VERSION ""

NS_ :

BS_:

BU_:

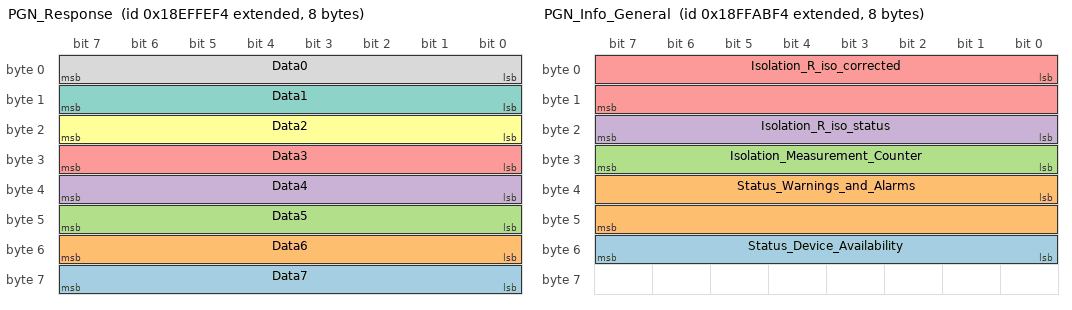
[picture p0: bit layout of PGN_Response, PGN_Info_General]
BO_ 2565865204 PGN_Response: 8 Vector__XXX
 SG_ Data7 : 56|8@1+ (1,0) [0|0] "" Vector__XXX
 SG_ Data6 : 48|8@1+ (1,0) [0|0] "" Vector__XXX
 SG_ Data5 : 40|8@1+ (1,0) [0|0] "" Vector__XXX
 SG_ Data4 : 32|8@1+ (1,0) [0|0] "" Vector__XXX
 SG_ Data3 : 24|8@1+ (1,0) [0|0] "" Vector__XXX
 SG_ Data2 : 16|8@1+ (1,0) [0|0] "" Vector__XXX
 SG_ Data1 : 8|8@1+ (1,0) [0|0] "" Vector__XXX
 SG_ Data0 : 0|8@1+ (1,0) [0|0] "" Vector__XXX

BO_ 2565862654 PGN_Request: 1 Vector__XXX
 SG_ Index : 0|8@1+ (1,0) [0|255] "" Vector__XXX

BO_ 2566892532 PGN_Info_General: 8 Vector__XXX
 SG_ Status_Device_Availability : 48|8@1+ (1,0) [0|255] "" Vector__XXX
 SG_ Status_Warnings_and_Alarms : 32|16@1+ (1,0) [0|65535] "" Vector__XXX
 SG_ Isolation_Measurement_Counter : 24|8@1+ (1,0) [0|255] "" Vector__XXX
 SG_ Isolation_R_iso_status : 16|8@1+ (1,0) [0|255] "" Vector__XXX
 SG_ Isolation_R_iso_corrected : 0|16@1+ (1,0) [0|65535] "" Vector__XXX

BA_DEF_ BO_  "J1939PgAppearanceOnBus" ENUM  "Default","CAN_Extended","CANFD_Extended";
BA_DEF_ BO_  "J1939CPgSendTimeout" INT -1 3600000;
BA_DEF_ BO_  "J1939CPgTOS" INT 0 7;
BA_DEF_ BU_  "J1939MultiPgSendTimeout" INT 0 3600000;
BA_DEF_ BU_  "J1939MultiPgSizeThreshold" INT 0 64;
BA_DEF_ BU_  "J1939MultiPgBroadcastType" ENUM  "FBFF","FEFF";
BA_DEF_ SG_  "SigType" ENUM  "Default","Range","RangeSigned","ASCII","Discrete","Control","ReferencePGN","DTC","StringDelimiter","StringLength","StringLengthControl","MessageCounter","MessageChecksum";
BA_DEF_ SG_  "GenSigILSupport" ENUM  "No","Yes";
BA_DEF_ SG_  "GenSigSendType" ENUM  "Cyclic","OnWrite","OnWriteWithRepetition","OnChange","OnChangeWithRepetition","IfActive","IfActiveWithRepetition","NoSigSendType";
BA_DEF_ BO_  "GenMsgILSupport" ENUM  "No","Yes";
BA_DEF_ BU_  "NmStationAddress" INT 0 255;
BA_DEF_ BO_  "GenMsgSendType" ENUM  "cyclic","NotUsed","NotUsed","NotUsed","NotUsed","NotUsed","NotUsed","IfActive","noMsgSendType";
BA_DEF_ BO_  "GenMsgRequestable" INT 0 1;
BA_DEF_  "DBName" STRING ;
BA_DEF_  "BusType" STRING ;
BA_DEF_  "ProtocolType" STRING ;
BA_DEF_ BO_  "VFrameFormat" ENUM  "StandardCAN","ExtendedCAN","reserved","J1939PG","reserved","reserved","reserved","reserved","reserved","reserved","reserved","reserved","reserved","reserved","StandardCAN_FD","ExtendedCAN_FD";
BA_DEF_DEF_  "J1939PgAppearanceOnBus" "Default";
BA_DEF_DEF_  "J1939CPgSendTimeout" -1;
BA_DEF_DEF_  "J1939CPgTOS" 2;
BA_DEF_DEF_  "J1939MultiPgSendTimeout" 2;
BA_DEF_DEF_  "J1939MultiPgSizeThreshold" 56;
BA_DEF_DEF_  "J1939MultiPgBroadcastType" "FBFF";
BA_DEF_DEF_  "SigType" "Default";
BA_DEF_DEF_  "GenSigILSupport" "Yes";
BA_DEF_DEF_  "GenSigSendType" "NoSigSendType";
BA_DEF_DEF_  "GenMsgILSupport" "Yes";
BA_DEF_DEF_  "NmStationAddress" 254;
BA_DEF_DEF_  "GenMsgSendType" "noMsgSendType";
BA_DEF_DEF_  "GenMsgRequestable" 1;
BA_DEF_DEF_  "DBName" "";
BA_DEF_DEF_  "BusType" "CAN";
BA_DEF_DEF_  "ProtocolType" "J1939";
BA_DEF_DEF_  "VFrameFormat" "J1939PG";
BA_ "DBName" "benderJ1939";
